# IVAHD_CM2 register map
Vendor: Texas Instruments
Peripheral module from a debugger description file (folder omap4460).
Registers are 32-bit, access per field, reset 0x3 unless marked. A register's access mark holds for its fields unless they carry their own. Offsets are as the file gives them; lines under a group give offsets from that group; [hi:lo] are bit positions; {n}, {i} and the like mark numbered series; 'fields as' and 'values as' point back to an identical list; <NAME> marks a mode.

## IVAHD_CM2
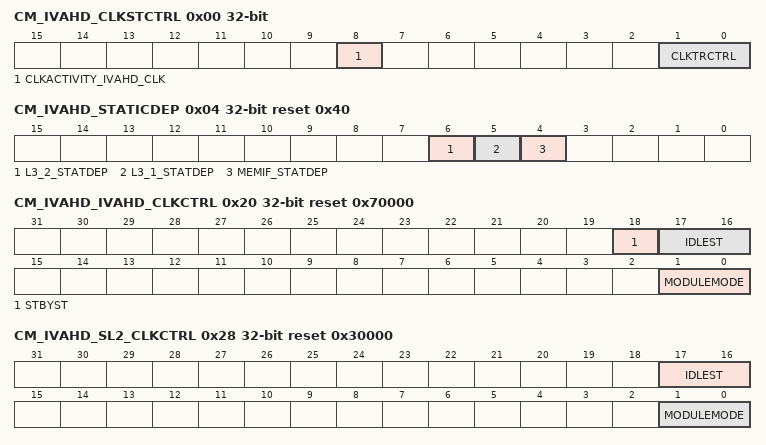
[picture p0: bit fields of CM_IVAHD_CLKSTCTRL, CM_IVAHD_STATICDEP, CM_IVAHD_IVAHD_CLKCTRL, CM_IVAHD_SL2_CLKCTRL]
0x00 CM_IVAHD_CLKSTCTRL — This register enables the IVAHD domain power state transition. It controls the hardware supervised domain power state transition between ON-ACTIVE and ON-INACTIVE states. It also holds 1 status bit per clock input of the domain.
  [8] CLKACTIVITY_IVAHD_CLK ro — This field indicates the state of the IVAHD_CLK clock input of the domain. [warm reset insensitive]
    0=CLKACTIVITY_IVAHD_CLK_0_r (Corresponding clock is definitely gated); 1=CLKACTIVITY_IVAHD_CLK_1_r (Corresponding clock is running or gating/ungating transition is ongoing)
  [1:0] CLKTRCTRL rw — Controls the clock state transition of the IVAHD clock domain.
    0=NO_SLEEP: Sleep transition cannot be initiated. Wakeup transition may however occur.; 1=SW_SLEEP: Start a software forced sleep transition on the domain; 2=SW_WKUP: Start a software forced wake-up transition on the domain; 3=HW_AUTO: Automatic transition is enabled. Sleep and wakeup transition are based upon hardware conditions.
0x04 CM_IVAHD_STATICDEP access not given reset 0x40 — This register controls the static domain depedencies from IVAHD domain towards 'target' domains. It is relevant only for domain having system initiator(s).
  [6] L3_2_STATDEP — Static dependency towards L3_2 clock domain (access R Rreturns1s)
    1=L3_2_STATDEP_1_r (Dependency is enabled)
  [5] L3_1_STATDEP rw — Static dependency towards L3_1 clock domain
    0=Dependency is disabled; 1=Dependency is enabled
  [4] MEMIF_STATDEP rw — Static dependency towards MEMIF clock domain
    0=Dependency is disabled; 1=Dependency is enabled
0x08 CM_IVAHD_DYNAMICDEP ro reset 0x0 — This register controls the dynamic domain depedencies from IVAHD domain towards 'target' domains. It is relevant only for domain having INTRCONN master port(s).
  [6] L3_2_DYNDEP — Dynamic dependency towards L3_2 clock domain
    0=L3_2_DYNDEP_0_r (Dependency is disabled)
0x20 CM_IVAHD_IVAHD_CLKCTRL reset 0x70000 — This register manages the IVAHD clocks.
  [18] STBYST ro — Module standby status. [warm reset insensitive]
    0=STBYST_0_r (Module is functional (not in standby)); 1=STBYST_1_r (Module is in standby)
  [17:16] IDLEST ro — Module idle status. [warm reset insensitive]
    0=IDLEST_0_r (Module is fully functional, including INTRCONN); 1=IDLEST_1_r (Module is performing transition: wakeup, or sleep, or sleep abortion); 2=IDLEST_2_r (Module is in idle mode (only INTRCONN part). It is functional if using separate functional clock); 3=IDLEST_3_r (Module is disabled and cannot be accessed)
  [1:0] MODULEMODE rw — Control the way mandatory clocks are managed.
    0=Module is disable by software. Any INTRCONN access to module results in an error, except if resulting from a module wakeup (asynchronous wakeup).; 1=Module is managed automatically by hardware according to clock domain transition. A clock domain sleep transition put module into idle. A wakeup domain transition put it back into function. If CLKTRCTRL=3, any INTRCONN access to module is always granted. Module clocks may be gated according to the clock domain state.; 2=MODULEMODE_2_r (Reserved); 3=MODULEMODE_3_r (Reserved)
0x28 CM_IVAHD_SL2_CLKCTRL reset 0x30000 — This register manages the SL2 clocks.
  [17:16] IDLEST ro — Module idle status. [warm reset insensitive]
    values as CM_IVAHD_IVAHD_CLKCTRL.IDLEST
  [1:0] MODULEMODE rw — Control the way mandatory clocks are managed.
    values as CM_IVAHD_IVAHD_CLKCTRL.MODULEMODE
